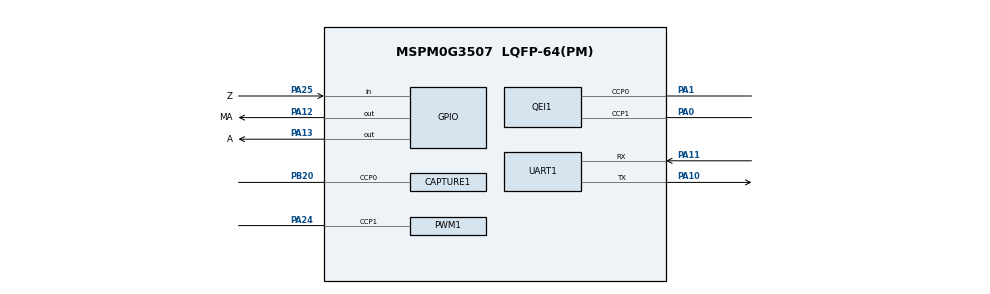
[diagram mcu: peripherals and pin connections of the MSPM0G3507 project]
/**
 * @cliArgs --device "MSPM0G3507" --package "LQFP-64(PM)" --product "mspm0_sdk@2.10.00.04"
 * @versions {"tool":"1.20.0+3587"}
 */

/**
 * Import the modules used in this configuration.
 */
const CAPTURE       = scripting.addModule("/ti/driverlib/CAPTURE", {}, false);
const CAPTURE1      = CAPTURE.addInstance();
const GPIO          = scripting.addModule("/ti/driverlib/GPIO", {}, false);
const GPIO1         = GPIO.addInstance();
const GPIO2         = GPIO.addInstance();
const GPIO3         = GPIO.addInstance();
const PWM           = scripting.addModule("/ti/driverlib/PWM", {}, false);
const PWM1          = PWM.addInstance();
const QEI           = scripting.addModule("/ti/driverlib/QEI", {}, false);
const QEI1          = QEI.addInstance();
const SYSCTL        = scripting.addModule("/ti/driverlib/SYSCTL");
const SYSTICK       = scripting.addModule("/ti/driverlib/SYSTICK");
const TIMER         = scripting.addModule("/ti/driverlib/TIMER", {}, false);
const TIMER1        = TIMER.addInstance();
const UART          = scripting.addModule("/ti/driverlib/UART", {}, false);
const UART1         = UART.addInstance();
const ProjectConfig = scripting.addModule("/ti/project_config/ProjectConfig");

/**
 * Write custom configuration values to the imported modules.
 */
const divider7       = system.clockTree["PLL_PDIV"];
divider7.divideValue = 2;

const divider9       = system.clockTree["UDIV"];
divider9.divideValue = 2;

const gate7  = system.clockTree["MFCLKGATE"];
gate7.enable = true;

const multiplier2         = system.clockTree["PLL_QDIV"];
multiplier2.multiplyValue = 5;

const mux8       = system.clockTree["HSCLKMUX"];
mux8.inputSelect = "HSCLKMUX_SYSPLL2X";

CAPTURE1.$name                              = "ENCODER_PWM";
CAPTURE1.captMode                           = "COMBINED";
CAPTURE1.timerPeriod                        = "50 ms";
CAPTURE1.timerStartTimer                    = true;
CAPTURE1.interrupts                         = ["CC0_DN","CC1_DN"];
CAPTURE1.peripheral.$assign                 = "TIMG12";
CAPTURE1.peripheral.ccp0Pin.$assign         = "PB20";
CAPTURE1.ccp0PinConfig.hideOutputInversion  = scripting.forceWrite(false);
CAPTURE1.ccp0PinConfig.onlyInternalResistor = scripting.forceWrite(false);
CAPTURE1.ccp0PinConfig.passedPeripheralType = scripting.forceWrite("Digital");
CAPTURE1.ccp0PinConfig.$name                = "ENCODER_PWM_PIN_CONFIG";

const Board = scripting.addModule("/ti/driverlib/Board", {}, false);

GPIO1.port                          = "PORTA";
GPIO1.$name                         = "DIR";
GPIO1.associatedPins[0].$name       = "A";
GPIO1.associatedPins[0].pin.$assign = "PA13";

GPIO2.$name                         = "EN";
GPIO2.associatedPins[0].$name       = "MA";
GPIO2.associatedPins[0].pin.$assign = "PA12";

GPIO3.$name                              = "ENCODER_Z";
GPIO3.associatedPins[0].$name            = "Z";
GPIO3.associatedPins[0].direction        = "INPUT";
GPIO3.associatedPins[0].internalResistor = "PULL_DOWN";
GPIO3.associatedPins[0].interruptEn      = true;
GPIO3.associatedPins[0].polarity         = "RISE";
GPIO3.associatedPins[0].pin.$assign      = "PA25";

PWM1.$name                      = "PWM_0";
PWM1.clockPrescale              = 80;
PWM1.ccIndex                    = [1];
PWM1.peripheral.ccp1Pin.$assign = "PA24";
PWM1.ccp1PinConfig.$name        = "ti_driverlib_gpio_GPIOPinGeneric1";
PWM1.PWM_CHANNEL_1.$name        = "ti_driverlib_pwm_PWMTimerCC1";

QEI1.$name                      = "QEI_0";
QEI1.timerStartTimer            = true;
QEI1.peripheral.$assign         = "TIMG8";
QEI1.peripheral.ccp0Pin.$assign = "PA1";
QEI1.peripheral.ccp1Pin.$assign = "PA0";
QEI1.ccp0PinConfig.$name        = "QEI_A_PIN_CONFIG";
QEI1.ccp1PinConfig.$name        = "QEI_B_PIN_CONFIG";

SYSCTL.forceDefaultClkConfig = true;
SYSCTL.clockTreeEn           = true;

SYSTICK.periodEnable  = true;
SYSTICK.systickEnable = true;
SYSTICK.period        = 16777216;

TIMER1.$name              = "TIMER_0";
TIMER1.timerClkPrescale   = 32;
TIMER1.timerMode          = "PERIODIC";
TIMER1.timerStartTimer    = true;
TIMER1.interrupts         = ["ZERO"];
TIMER1.timerPeriod        = "5 ms";
TIMER1.peripheral.$assign = "TIMG0";

UART1.$name                    = "UART_0";
UART1.targetBaudRate           = 115200;
UART1.enableFIFO               = true;
UART1.peripheral.rxPin.$assign = "PA11";
UART1.peripheral.txPin.$assign = "PA10";
UART1.txPinConfig.$name        = "ti_driverlib_gpio_GPIOPinGeneric2";
UART1.rxPinConfig.$name        = "ti_driverlib_gpio_GPIOPinGeneric3";

ProjectConfig.genLinker = false;

/**
 * Pinmux solution for unlocked pins/peripherals. This ensures that minor changes to the automatic solver in a future
 * version of the tool will not impact the pinmux you originally saw.  These lines can be completely deleted in order to
 * re-solve from scratch.
 */
Board.peripheral.$suggestSolution          = "DEBUGSS";
Board.peripheral.swclkPin.$suggestSolution = "PA20";
Board.peripheral.swdioPin.$suggestSolution = "PA19";
PWM1.peripheral.$suggestSolution           = "TIMA1";
UART1.peripheral.$suggestSolution          = "UART0";
